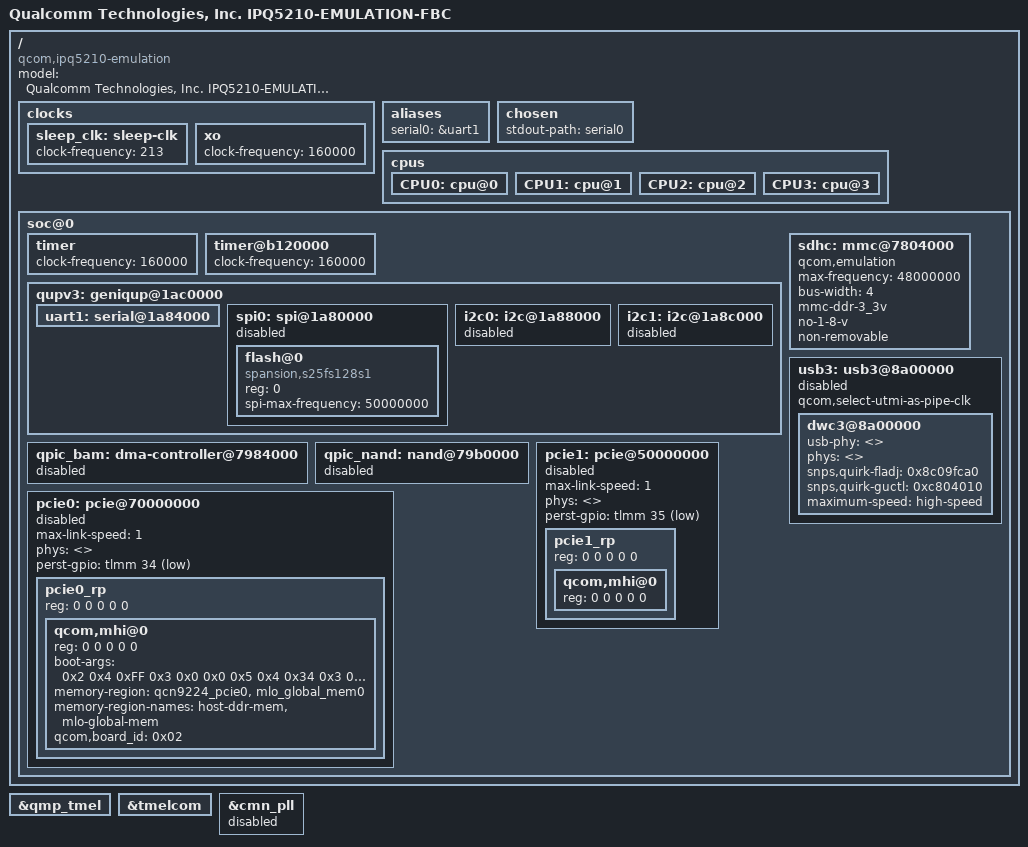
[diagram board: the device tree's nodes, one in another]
// SPDX-License-Identifier: (GPL-2.0+ OR BSD-3-Clause)
/*
 * IPQ5210 Emulation FBC board device tree source
 *
 * Copyright (c) 2020-2021 The Linux Foundation. All rights reserved.
 * Copyright (c) Qualcomm Technologies, Inc. and/or its subsidiaries.
 */

/dts-v1/;

#include "ipq5210.dtsi"
#include "ipq5210-default-memory.dtsi"

/ {
	model = "Qualcomm Technologies, Inc. IPQ5210-EMULATION-FBC";
	compatible = "qcom,ipq5210-emulation", "qcom,ipq5210";

	/* Timer freq for rumi = timer freq / 150 */
	clocks {
		sleep_clk: sleep-clk {
			clock-frequency = <213>;
		};

		xo: xo {
			clock-frequency = <160000>;
		};
	};

	aliases {
		serial0 = &uart1;
	};

	chosen {
		stdout-path = "serial0";
	};

	cpus: cpus {
		CPU0: cpu@0 {
			/delete-property/ clocks;
			/delete-property/ clock-names;
			/delete-property/ operating-points-v2;
		};

		CPU1: cpu@1 {
			/delete-property/ clocks;
			/delete-property/ clock-names;
			/delete-property/ operating-points-v2;
		};

		CPU2: cpu@2 {
			/delete-property/ clocks;
			/delete-property/ clock-names;
			/delete-property/ operating-points-v2;
		};

		CPU3: cpu@3 {
			/delete-property/ clocks;
			/delete-property/ clock-names;
			/delete-property/ operating-points-v2;
		};
	};

	soc@0 {
		/* Timer freq for rumi = timer freq / 150 */
		timer {
			clock-frequency = <160000>;
		};

		timer@b120000 {
			clock-frequency = <160000>;
		};

		qupv3: geniqup@1ac0000 {
			status = "okay";

			uart1: serial@1a84000 {
				status = "okay";
			};

			spi0: spi@1a80000 {
				status = "disabled";

				flash@0 {
					compatible = "spansion,s25fs128s1", "jedec,spi-nor";
					#address-cells = <1>;
					#size-cells = <1>;
					reg = <0>;
					spi-max-frequency = <50000000>;
				};
			};

			i2c0: i2c@1a88000 {
				status = "disabled";
			};

			i2c1: i2c@1a8c000 {
				status = "disabled";
			};
		};

		sdhc: mmc@7804000 {
			qcom,emulation;
			/* over-ride the frequency to 48Mhz for emulation platform */
			max-frequency = <48000000>;
			bus-width = <4>;
			/* Force 3.3V, because only that will support on emulation platform */
			mmc-ddr-3_3v;
			/* quirk to disable SDR104, SDR50 modes */
			no-1-8-v;
			non-removable;
			status = "okay";
		};

		usb3: usb3@8a00000 {
			qcom,select-utmi-as-pipe-clk;
			status = "disabled";

			dwc3@8a00000 {
				usb-phy = <>;
				phys = <>;
				phy-names = "";
				snps,quirk-fladj = <0x8c09fca0>;
				snps,quirk-guctl = <0xc804010>;
				maximum-speed = "high-speed";
			};
		};

		qpic_bam: dma-controller@7984000 {
			status="disabled";
		};

		qpic_nand: nand@79b0000 {
			status="disabled";
		};

		pcie0: pcie@70000000 {
			max-link-speed = <1>;
			phys = <>;
			phy-names = "";
			perst-gpio = <&tlmm 34 GPIO_ACTIVE_LOW>;
			status = "disabled";

			pcie0_rp {
				reg = <0 0 0 0 0>;
				qcom,mhi@0 {
					reg = <0 0 0 0 0>;
					boot-args = <0x2 0x4 0xFF 0x3 0x0 0x0  /* MX Rail, Invalid GPIO, Drive strength 0x3 */
							0x5 0x4 0x34 0x3 0x0 0x16 /* CX Rail, GPIO52, Drive strength 0x3, CPR1_fuse 0x0, CPR0_fuse 0x16 */
							0x0 0x4 0x0 0x0 0x0 0x0>; /* End of arguments */
					memory-region = <&qcn9224_pcie0>, <&mlo_global_mem0>;
					memory-region-names = "host-ddr-mem", "mlo-global-mem";
					qcom,board_id = <0x02>;
				};
			};
		};

		pcie1: pcie@50000000 {
			max-link-speed = <1>;
			phys = <>;
			phy-names = "";
			perst-gpio = <&tlmm 35 GPIO_ACTIVE_LOW>;
			status = "disabled";

			pcie1_rp {
				reg = <0 0 0 0 0>;
				qcom,mhi@0 {
					reg = <0 0 0 0 0>;
				};
			};
		};
	};
};

&qmp_tmel {
	status = "okay";
};

&tmelcom {
	status = "okay";
};

&cmn_pll {
	status = "disabled";
};
